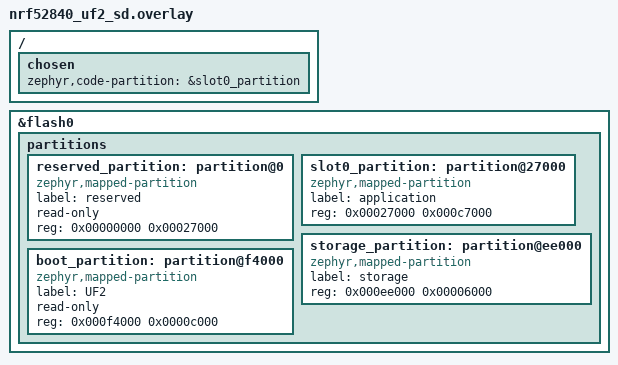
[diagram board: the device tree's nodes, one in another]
/ {
	chosen {
		zephyr,code-partition = &slot0_partition;
	};
};

&flash0 {
	/delete-node/ partitions;

	partitions {
		ranges;
		#address-cells = <1>;
		#size-cells = <1>;

		reserved_partition: partition@0 {
			compatible = "zephyr,mapped-partition";
			label = "reserved";
			read-only;
			reg = <0x00000000 0x00027000>;
		};

		slot0_partition: partition@27000 {
			compatible = "zephyr,mapped-partition";
			label = "application";
			reg = <0x00027000 0x000c7000>;
		};

		storage_partition: partition@ee000 {
			compatible = "zephyr,mapped-partition";
			label = "storage";
			reg = <0x000ee000 0x00006000>;
		};

		boot_partition: partition@f4000 {
			compatible = "zephyr,mapped-partition";
			label = "UF2";
			read-only;
			reg = <0x000f4000 0x0000c000>;
		};
	};
};
